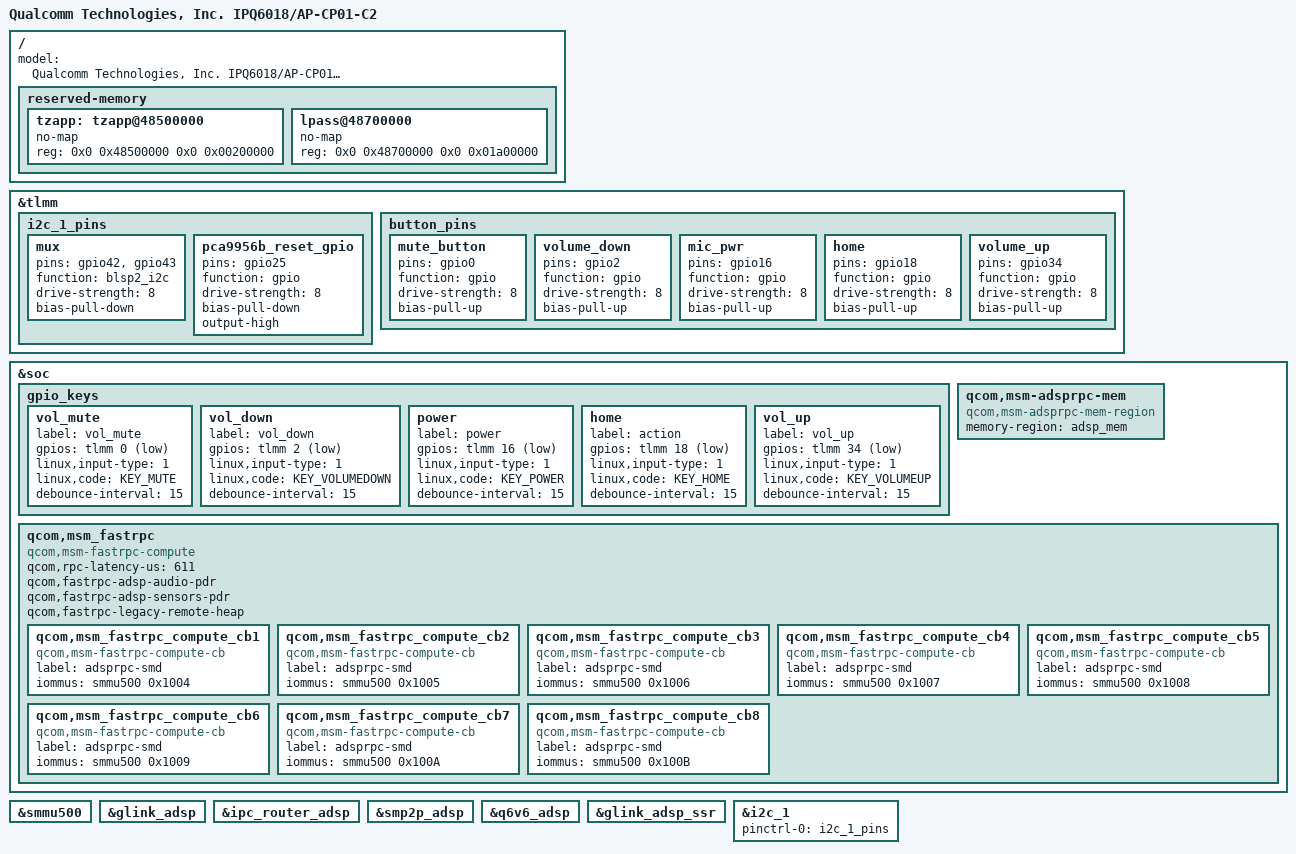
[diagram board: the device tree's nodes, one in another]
/dts-v1/;
/*
 * Copyright (c) 2019, The Linux Foundation. All rights reserved.
 *
 * Permission to use, copy, modify, and/or distribute this software for any
 * purpose with or without fee is hereby granted, provided that the above
 * copyright notice and this permission notice appear in all copies.
 *
 * THE SOFTWARE IS PROVIDED "AS IS" AND THE AUTHOR DISCLAIMS ALL WARRANTIES
 * WITH REGARD TO THIS SOFTWARE INCLUDING ALL IMPLIED WARRANTIES OF
 * MERCHANTABILITY AND FITNESS. IN NO EVENT SHALL THE AUTHOR BE LIABLE FOR
 * ANY SPECIAL, DIRECT, INDIRECT, OR CONSEQUENTIAL DAMAGES OR ANY DAMAGES
 * WHATSOEVER RESULTING FROM LOSS OF USE, DATA OR PROFITS, WHETHER IN AN
 * ACTION OF CONTRACT, NEGLIGENCE OR OTHER TORTIOUS ACTION, ARISING OUT OF
 * OR IN CONNECTION WITH THE USE OR PERFORMANCE OF THIS SOFTWARE.
 */

#include "qcom-ipq6018-cp01.dtsi"
#include "qcom-ipq6018-ion.dtsi"
#include "qcom-ipq6018-audio-overlay.dtsi"
#include "qcom-ipq6018-circular-pca9956.dtsi"

/ {
	model = "Qualcomm Technologies, Inc. IPQ6018/AP-CP01-C2";

	/*
	 * +=========+==============+========================+
	 * |        |              |                         |
	 * | Region | Start Offset |          Size           |
	 * |        |              |                         |
	 * +--------+--------------+-------------------------+
	 * |        |              |                         |
	 * |        |              |                         |
	 * |        |              |                         |
	 * |        |              |                         |
	 * | Linux  |  0x41000000  |         117MB           |
	 * |        |              |                         |
	 * |        |              |                         |
	 * |        |              |                         |
	 * +--------+--------------+-------------------------+
	 * | TZ App |  0x48500000  |           2MB           |
	 * +--------+--------------+-------------------------+
	 * |        |              |                         |
	 * | LPASS  |              |                         |
	 * |   Q6   |  0x48700000  |          26MB           |
	 * |        |              |                         |
	 * +--------+--------------+-------------------------+
	 *
	 * From the available 145 MB for Linux in the first 256 MB,
	 * we are reserving 26 MB for LPASS and 2 MB for TZAPP.
	 *
	 * Refer arch/arm64/boot/dts/qcom/qcom-ipq6018-memory.dtsi
	 * for memory layout.
	 */

	reserved-memory {
		tzapp:tzapp@48500000 {	/* TZAPPS */
			no-map;
			reg = <0x0 0x48500000 0x0 0x00200000>;
		};

		lpass@48700000 {
			no-map;
			reg = <0x0 0x48700000 0x0 0x01a00000>;
		};
	};
};

&tlmm {
	i2c_1_pins: i2c_1_pins {
		mux {
			pins = "gpio42", "gpio43";
			function = "blsp2_i2c";
			drive-strength = <8>;
			bias-pull-down;
		};
		pca9956b_reset_gpio {
			pins = "gpio25";
			function = "gpio";
			drive-strength = <8>;
			bias-pull-down;
			output-high;
		};
	};

	button_pins: button_pins {
		mute_button {
			pins = "gpio0";
			function = "gpio";
			drive-strength = <8>;
			bias-pull-up;
		};
		volume_down {
			pins = "gpio2";
			function = "gpio";
			drive-strength = <8>;
			bias-pull-up;
		};
		mic_pwr {
			pins = "gpio16";
			function = "gpio";
			drive-strength = <8>;
			bias-pull-up;
		};
		home {
			pins = "gpio18";
			function = "gpio";
			drive-strength = <8>;
			bias-pull-up;
		};
		volume_up {
			pins = "gpio34";
			function = "gpio";
			drive-strength = <8>;
			bias-pull-up;
		};
	};

};

&soc {
	gpio_keys {
		vol_mute {
			label = "vol_mute";
			gpios = <&tlmm 0 GPIO_ACTIVE_LOW>;
			linux,input-type = <1>;
			linux,code = <KEY_MUTE>;
			debounce-interval = <15>;
		};

		vol_down {
			label = "vol_down";
			gpios = <&tlmm 2 GPIO_ACTIVE_LOW>;
			linux,input-type = <1>;
			linux,code = <KEY_VOLUMEDOWN>;
			debounce-interval = <15>;
		};

		power {
			label = "power";
			gpios = <&tlmm 16 GPIO_ACTIVE_LOW>;
			linux,input-type = <1>;
			linux,code = <KEY_POWER>;
			debounce-interval = <15>;
		};

		home {
			label = "action";
			gpios = <&tlmm 18 GPIO_ACTIVE_LOW>;
			linux,input-type = <1>;
			linux,code = <KEY_HOME>;
			debounce-interval = <15>;
		};

		vol_up {
			label = "vol_up";
			gpios = <&tlmm 34 GPIO_ACTIVE_LOW>;
			linux,input-type = <1>;
			linux,code = <KEY_VOLUMEUP>;
			debounce-interval = <15>;
		};
	};

	qcom,msm-adsprpc-mem {
		compatible = "qcom,msm-adsprpc-mem-region";
		memory-region = <&adsp_mem>;
	};

	qcom,msm_fastrpc {
		compatible = "qcom,msm-fastrpc-compute";
		qcom,rpc-latency-us = <611>;
		qcom,fastrpc-adsp-audio-pdr;
		qcom,fastrpc-adsp-sensors-pdr;
		qcom,fastrpc-legacy-remote-heap;

		qcom,msm_fastrpc_compute_cb1 {
			compatible = "qcom,msm-fastrpc-compute-cb";
			label = "adsprpc-smd";
			iommus = <&smmu500 0x1004>;
		};

		qcom,msm_fastrpc_compute_cb2 {
			compatible = "qcom,msm-fastrpc-compute-cb";
			label = "adsprpc-smd";
			iommus = <&smmu500 0x1005>;
		};

		qcom,msm_fastrpc_compute_cb3 {
			compatible = "qcom,msm-fastrpc-compute-cb";
			label = "adsprpc-smd";
			iommus = <&smmu500 0x1006>;
		};

		qcom,msm_fastrpc_compute_cb4 {
			compatible = "qcom,msm-fastrpc-compute-cb";
			label = "adsprpc-smd";
			iommus = <&smmu500 0x1007>;
		};

		qcom,msm_fastrpc_compute_cb5 {
			compatible = "qcom,msm-fastrpc-compute-cb";
			label = "adsprpc-smd";
			iommus = <&smmu500 0x1008>;
		};

		qcom,msm_fastrpc_compute_cb6 {
			compatible = "qcom,msm-fastrpc-compute-cb";
			label = "adsprpc-smd";
			iommus = <&smmu500 0x1009>;
		};

		qcom,msm_fastrpc_compute_cb7 {
			compatible = "qcom,msm-fastrpc-compute-cb";
			label = "adsprpc-smd";
			iommus = <&smmu500 0x100A>;
		};

		qcom,msm_fastrpc_compute_cb8 {
			compatible = "qcom,msm-fastrpc-compute-cb";
			label = "adsprpc-smd";
			iommus = <&smmu500 0x100B>;
		};
	};
};

&smmu500 {
	status = "ok";
};

&glink_adsp {
	status = "ok";
};

&ipc_router_adsp {
	status = "ok";
};

&smp2p_adsp {
	status = "ok";
};

&q6v6_adsp {
	status = "ok";
};

&glink_adsp_ssr {
	status = "ok";
};

&i2c_1 {
	pinctrl-0 = <&i2c_1_pins>;
	pinctrl-names = "default";
};
